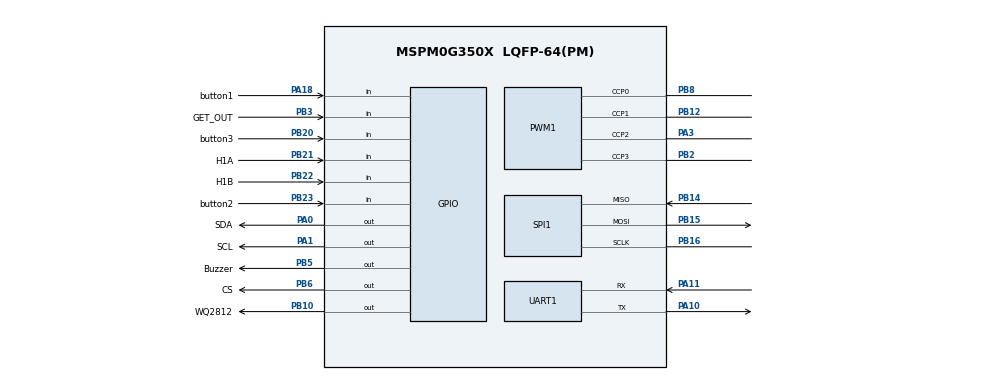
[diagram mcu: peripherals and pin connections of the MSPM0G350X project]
/**
 * @cliArgs --device "MSPM0G350X" --part "Default" --package "LQFP-64(PM)" --product "mspm0_sdk@2.10.00.04"
 * @versions {"tool":"1.28.0+4712"}
 */

/**
 * Import the modules used in this configuration.
 */
const ADC12   = scripting.addModule("/ti/driverlib/ADC12", {}, false);
const ADC121  = ADC12.addInstance();
const GPIO    = scripting.addModule("/ti/driverlib/GPIO", {}, false);
const GPIO1   = GPIO.addInstance();
const GPIO2   = GPIO.addInstance();
const GPIO3   = GPIO.addInstance();
const GPIO4   = GPIO.addInstance();
const GPIO5   = GPIO.addInstance();
const GPIO6   = GPIO.addInstance();
const GPIO7   = GPIO.addInstance();
const GPIO8   = GPIO.addInstance();
const GPIO9   = GPIO.addInstance();
const GPIO10  = GPIO.addInstance();
const GPIO11  = GPIO.addInstance();
const PWM     = scripting.addModule("/ti/driverlib/PWM", {}, false);
const PWM1    = PWM.addInstance();
const SPI     = scripting.addModule("/ti/driverlib/SPI", {}, false);
const SPI1    = SPI.addInstance();
const SYSCTL  = scripting.addModule("/ti/driverlib/SYSCTL");
const SYSTICK = scripting.addModule("/ti/driverlib/SYSTICK");
const TIMER   = scripting.addModule("/ti/driverlib/TIMER", {}, false);
const TIMER1  = TIMER.addInstance();
const TIMER2  = TIMER.addInstance();
const UART    = scripting.addModule("/ti/driverlib/UART", {}, false);
const UART1   = UART.addInstance();

/**
 * Write custom configuration values to the imported modules.
 */
const divider7       = system.clockTree["PLL_PDIV"];
divider7.divideValue = 2;

const divider9       = system.clockTree["UDIV"];
divider9.divideValue = 2;

const gate7  = system.clockTree["MFCLKGATE"];
gate7.enable = true;

const multiplier2         = system.clockTree["PLL_QDIV"];
multiplier2.multiplyValue = 8;

const mux4       = system.clockTree["EXHFMUX"];
mux4.inputSelect = "EXHFMUX_XTAL";

const mux8       = system.clockTree["HSCLKMUX"];
mux8.inputSelect = "HSCLKMUX_SYSPLL0";

const mux12       = system.clockTree["SYSPLLMUX"];
mux12.inputSelect = "zSYSPLLMUX_HFCLK";

const pinFunction4        = system.clockTree["HFXT"];
pinFunction4.inputFreq    = 40;
pinFunction4.enable       = true;
pinFunction4.HFCLKMonitor = true;
pinFunction4.HFXTStartup  = 100;

ADC121.$name                      = "ADC_Senor";
ADC121.samplingOperationMode      = "sequence";
ADC121.sampClkDiv                 = "DL_ADC12_CLOCK_DIVIDE_8";
ADC121.adcMem0_name               = "IR_left";
ADC121.adcMem0chansel             = "DL_ADC12_INPUT_CHAN_2";
ADC121.adcMem1_name               = "IR_right";
ADC121.adcMem1chansel             = "DL_ADC12_INPUT_CHAN_4";
ADC121.adcMem2_name               = "light_left";
ADC121.adcMem2chansel             = "DL_ADC12_INPUT_CHAN_5";
ADC121.adcMem3_name               = "light_right";
ADC121.adcMem3chansel             = "DL_ADC12_INPUT_CHAN_3";
ADC121.sampleTime0                = "5 ms";
ADC121.endAdd                     = 4;
ADC121.enabledInterrupts          = ["DL_ADC12_INTERRUPT_MEM4_RESULT_LOADED"];
ADC121.peripheral.adcPin2.$assign = "PA25";
ADC121.peripheral.adcPin4.$assign = "PB25";
ADC121.peripheral.adcPin5.$assign = "PB24";
ADC121.peripheral.adcPin3.$assign = "PA24";
ADC121.peripheral.adcPin0.$assign = "PA27";
ADC121.adcPin2Config.$name        = "ti_driverlib_gpio_GPIOPinGeneric3";
ADC121.adcPin0Config.$name        = "ti_driverlib_gpio_GPIOPinGeneric6";
ADC121.adcPin3Config.$name        = "ti_driverlib_gpio_GPIOPinGeneric2";
ADC121.adcPin4Config.$name        = "ti_driverlib_gpio_GPIOPinGeneric4";
ADC121.adcPin5Config.$name        = "ti_driverlib_gpio_GPIOPinGeneric5";

const Board = scripting.addModule("/ti/driverlib/Board", {}, false);

GPIO1.$name                              = "LED";
GPIO1.port                               = "PORTA";
GPIO1.associatedPins[0].internalResistor = "PULL_DOWN";
GPIO1.associatedPins[0].assignedPin      = "17";
GPIO1.associatedPins[0].$name            = "MCU";

GPIO2.$name                         = "BEEP";
GPIO2.port                          = "PORTB";
GPIO2.associatedPins[0].$name       = "Buzzer";
GPIO2.associatedPins[0].assignedPin = "5";
GPIO2.associatedPins[0].pin.$assign = "PB5";

GPIO3.$name                         = "KEY";
GPIO3.associatedPins.create(3);
GPIO3.associatedPins[0].$name       = "button1";
GPIO3.associatedPins[0].direction   = "INPUT";
GPIO3.associatedPins[0].assignedPin = "18";
GPIO3.associatedPins[0].pin.$assign = "PA18";
GPIO3.associatedPins[1].$name       = "button2";
GPIO3.associatedPins[1].direction   = "INPUT";
GPIO3.associatedPins[1].assignedPin = "23";
GPIO3.associatedPins[1].pin.$assign = "PB23";
GPIO3.associatedPins[2].$name       = "button3";
GPIO3.associatedPins[2].direction   = "INPUT";
GPIO3.associatedPins[2].assignedPin = "20";
GPIO3.associatedPins[2].pin.$assign = "PB20";

GPIO4.$name                          = "RGB";
GPIO4.associatedPins[0].$name        = "WQ2812";
GPIO4.associatedPins[0].ioStructure  = "SD";
GPIO4.associatedPins[0].assignedPin  = "10";
GPIO4.associatedPins[0].assignedPort = "PORTB";
GPIO4.associatedPins[0].pin.$assign  = "PB10";

GPIO5.$name                         = "Infrared_borad";
GPIO5.associatedPins[0].$name       = "IR_switch";
GPIO5.associatedPins[0].assignedPin = "9";

GPIO6.$name                         = "IRContorl";
GPIO6.port                          = "PORTB";
GPIO6.associatedPins[0].$name       = "GET_OUT";
GPIO6.associatedPins[0].direction   = "INPUT";
GPIO6.associatedPins[0].assignedPin = "3";
GPIO6.associatedPins[0].interruptEn = true;
GPIO6.associatedPins[0].polarity    = "FALL";
GPIO6.associatedPins[0].pin.$assign = "PB3";

GPIO7.$name                               = "GPIO_ENCODER_L";
GPIO7.port                                = "PORTB";
GPIO7.associatedPins.create(2);
GPIO7.associatedPins[0].$name             = "H1A";
GPIO7.associatedPins[0].direction         = "INPUT";
GPIO7.associatedPins[0].assignedPin       = "21";
GPIO7.associatedPins[0].interruptEn       = true;
GPIO7.associatedPins[0].interruptPriority = "0";
GPIO7.associatedPins[0].polarity          = "RISE";
GPIO7.associatedPins[0].pin.$assign       = "PB21";
GPIO7.associatedPins[1].$name             = "H1B";
GPIO7.associatedPins[1].direction         = "INPUT";
GPIO7.associatedPins[1].assignedPin       = "22";
GPIO7.associatedPins[1].interruptEn       = true;
GPIO7.associatedPins[1].interruptPriority = "0";
GPIO7.associatedPins[1].polarity          = "RISE";
GPIO7.associatedPins[1].pin.$assign       = "PB22";

GPIO8.$name                               = "GPIO_ENCODER_R";
GPIO8.associatedPins.create(2);
GPIO8.associatedPins[0].direction         = "INPUT";
GPIO8.associatedPins[0].interruptEn       = true;
GPIO8.associatedPins[0].interruptPriority = "0";
GPIO8.associatedPins[0].polarity          = "RISE";
GPIO8.associatedPins[0].$name             = "H2A";
GPIO8.associatedPins[0].assignedPin       = "13";
GPIO8.associatedPins[0].assignedPort      = "PORTB";
GPIO8.associatedPins[1].direction         = "INPUT";
GPIO8.associatedPins[1].interruptEn       = true;
GPIO8.associatedPins[1].interruptPriority = "0";
GPIO8.associatedPins[1].polarity          = "RISE";
GPIO8.associatedPins[1].$name             = "H2B";
GPIO8.associatedPins[1].assignedPort      = "PORTA";
GPIO8.associatedPins[1].assignedPin       = "31";

GPIO9.$name                          = "OLED";
GPIO9.port                           = "PORTA";
GPIO9.associatedPins.create(2);
GPIO9.associatedPins[0].initialValue = "SET";
GPIO9.associatedPins[0].assignedPin  = "15";
GPIO9.associatedPins[0].$name        = "SCL1";
GPIO9.associatedPins[1].initialValue = "SET";
GPIO9.associatedPins[1].assignedPin  = "30";
GPIO9.associatedPins[1].$name        = "SDA1";

GPIO10.$name                          = "SPI";
GPIO10.associatedPins[0].$name        = "CS";
GPIO10.associatedPins[0].assignedPin  = "6";
GPIO10.associatedPins[0].initialValue = "SET";
GPIO10.associatedPins[0].pin.$assign  = "PB6";

GPIO11.$name                          = "MPU6050";
GPIO11.associatedPins.create(2);
GPIO11.associatedPins[0].initialValue = "SET";
GPIO11.associatedPins[0].$name        = "SDA";
GPIO11.associatedPins[0].ioStructure  = "OD";
GPIO11.associatedPins[0].pin.$assign  = "PA0";
GPIO11.associatedPins[1].initialValue = "SET";
GPIO11.associatedPins[1].$name        = "SCL";
GPIO11.associatedPins[1].ioStructure  = "OD";
GPIO11.associatedPins[1].pin.$assign  = "PA1";

PWM1.$name                              = "motor_PWM";
PWM1.ccIndex                            = [0,1,2,3];
PWM1.clockDivider                       = 2;
PWM1.peripheral.$assign                 = "TIMA0";
PWM1.peripheral.ccp0Pin.$assign         = "PB8";
PWM1.peripheral.ccp1Pin.$assign         = "PB12";
PWM1.peripheral.ccp2Pin.$assign         = "PA3";
PWM1.peripheral.ccp3Pin.$assign         = "PB2";
PWM1.PWM_CHANNEL_0.$name                = "ti_driverlib_pwm_PWMTimerCC0";
PWM1.PWM_CHANNEL_1.$name                = "ti_driverlib_pwm_PWMTimerCC1";
PWM1.ccp0PinConfig.direction            = scripting.forceWrite("OUTPUT");
PWM1.ccp0PinConfig.hideOutputInversion  = scripting.forceWrite(false);
PWM1.ccp0PinConfig.onlyInternalResistor = scripting.forceWrite(false);
PWM1.ccp0PinConfig.passedPeripheralType = scripting.forceWrite("Digital");
PWM1.ccp0PinConfig.$name                = "ti_driverlib_gpio_GPIOPinGeneric7";
PWM1.ccp1PinConfig.direction            = scripting.forceWrite("OUTPUT");
PWM1.ccp1PinConfig.hideOutputInversion  = scripting.forceWrite(false);
PWM1.ccp1PinConfig.onlyInternalResistor = scripting.forceWrite(false);
PWM1.ccp1PinConfig.passedPeripheralType = scripting.forceWrite("Digital");
PWM1.ccp1PinConfig.$name                = "ti_driverlib_gpio_GPIOPinGeneric8";
PWM1.PWM_CHANNEL_2.$name                = "ti_driverlib_pwm_PWMTimerCC2";
PWM1.PWM_CHANNEL_3.$name                = "ti_driverlib_pwm_PWMTimerCC3";
PWM1.ccp2PinConfig.$name                = "ti_driverlib_gpio_GPIOPinGeneric9";
PWM1.ccp3PinConfig.$name                = "ti_driverlib_gpio_GPIOPinGeneric10";

SPI1.$name                              = "SPI_W25Q64";
SPI1.frameFormat                        = "MOTO3";
SPI1.targetBitRate                      = 10000000;
SPI1.peripheral.$assign                 = "SPI1";
SPI1.peripheral.sclkPin.$assign         = "PB16";
SPI1.peripheral.mosiPin.$assign         = "PB15";
SPI1.peripheral.misoPin.$assign         = "PB14";
SPI1.sclkPinConfig.direction            = scripting.forceWrite("OUTPUT");
SPI1.sclkPinConfig.onlyInternalResistor = scripting.forceWrite(false);
SPI1.sclkPinConfig.passedPeripheralType = scripting.forceWrite("Digital");
SPI1.sclkPinConfig.$name                = "ti_driverlib_gpio_GPIOPinGeneric11";
SPI1.mosiPinConfig.direction            = scripting.forceWrite("OUTPUT");
SPI1.mosiPinConfig.hideOutputInversion  = scripting.forceWrite(false);
SPI1.mosiPinConfig.onlyInternalResistor = scripting.forceWrite(false);
SPI1.mosiPinConfig.passedPeripheralType = scripting.forceWrite("Digital");
SPI1.mosiPinConfig.$name                = "ti_driverlib_gpio_GPIOPinGeneric12";
SPI1.misoPinConfig.onlyInternalResistor = scripting.forceWrite(false);
SPI1.misoPinConfig.passedPeripheralType = scripting.forceWrite("Digital");
SPI1.misoPinConfig.$name                = "ti_driverlib_gpio_GPIOPinGeneric13";

SYSCTL.forceDefaultClkConfig = true;
SYSCTL.clockTreeEn           = true;
SYSCTL.validateClkStatus     = true;

SYSTICK.periodEnable      = true;
SYSTICK.systickEnable     = true;
SYSTICK.interruptPriority = "0";
SYSTICK.period            = 80;

TIMER1.$name             = "TIMER_20ms";
TIMER1.timerPeriod       = "20 ms";
TIMER1.timerMode         = "PERIODIC";
TIMER1.timerClkPrescale  = 10;
TIMER1.interrupts        = ["ZERO"];
TIMER1.interruptPriority = "3";
TIMER1.timerClkDiv       = 8;

TIMER2.$name             = "TIMER_1ms";
TIMER2.timerPeriod       = "1 ms";
TIMER2.timerClkSrc       = "MFCLK";
TIMER2.timerClkDiv       = 5;
TIMER2.timerMode         = "PERIODIC_UP";
TIMER2.interrupts        = ["LOAD"];
TIMER2.interruptPriority = "0";

UART1.$name                    = "UART_0";
UART1.enabledInterrupts        = ["RX"];
UART1.targetBaudRate           = 115200;
UART1.uartClkDiv               = "4";
UART1.peripheral.$assign       = "UART0";
UART1.peripheral.rxPin.$assign = "PA11";
UART1.peripheral.txPin.$assign = "PA10";
UART1.txPinConfig.$name        = "ti_driverlib_gpio_GPIOPinGeneric0";
UART1.rxPinConfig.$name        = "ti_driverlib_gpio_GPIOPinGeneric1";

/**
 * Pinmux solution for unlocked pins/peripherals. This ensures that minor changes to the automatic solver in a future
 * version of the tool will not impact the pinmux you originally saw.  These lines can be completely deleted in order to
 * re-solve from scratch.
 */
pinFunction4.peripheral.$suggestSolution           = "SYSCTL";
pinFunction4.peripheral.hfxInPin.$suggestSolution  = "PA5";
pinFunction4.peripheral.hfxOutPin.$suggestSolution = "PA6";
ADC121.peripheral.$suggestSolution                 = "ADC0";
Board.peripheral.$suggestSolution                  = "DEBUGSS";
Board.peripheral.swclkPin.$suggestSolution         = "PA20";
Board.peripheral.swdioPin.$suggestSolution         = "PA19";
GPIO1.associatedPins[0].pin.$suggestSolution       = "PA17";
GPIO5.associatedPins[0].pin.$suggestSolution       = "PA9";
GPIO8.associatedPins[0].pin.$suggestSolution       = "PB13";
GPIO8.associatedPins[1].pin.$suggestSolution       = "PA31";
GPIO9.associatedPins[0].pin.$suggestSolution       = "PA15";
GPIO9.associatedPins[1].pin.$suggestSolution       = "PA30";
TIMER1.peripheral.$suggestSolution                 = "TIMG0";
TIMER2.peripheral.$suggestSolution                 = "TIMA1";
